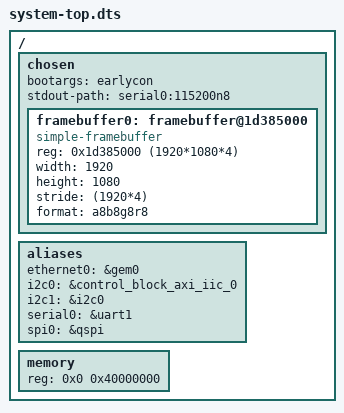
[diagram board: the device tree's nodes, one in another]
/*
 * CAUTION: This file is automatically generated by Xilinx.
 * Version: HSI 2017.4
 * Today is: Thu Apr 11 12:25:42 2019
 */


/dts-v1/;
/include/ "zynq-7000.dtsi"
/include/ "pl.dtsi"
/include/ "pcw.dtsi"
/ {
	chosen {
		bootargs = "earlycon";
		stdout-path = "serial0:115200n8";
		#address-cells = <0x1>;
		#size-cells = <0x1>;
		ranges;
		framebuffer0: framebuffer@1d385000{
			compatible = "simple-framebuffer";
			reg = <0x1d385000 (1920*1080*4)>;
			width = <1920>;
			height = <1080>;
			stride = <(1920*4)>;
			format = "a8b8g8r8";	
			status = "okay";
		};
	};
	aliases {
		ethernet0 = &gem0;
		i2c0 = &control_block_axi_iic_0;
		i2c1 = &i2c0;
		serial0 = &uart1;
		spi0 = &qspi;
		/*display0 = <&lcdc0>;*/
	};
	memory {
		device_type = "memory";
		reg = <0x0 0x40000000>;
	};
};

/*In framebuffer:
 * r5g6b5: 16 bit colour depth (2 bytes)
 * a8b8g8r8: 32 bit colour depth (4 bytes)
 * Optional settings
 * clocks = <&ahb_gates 36>, <&ahb_gates 43>, <&ahb_gates 44>;
 * lcd-supply = <&reg_dc1sw>;
 * display = <&lcdc0>;*/
